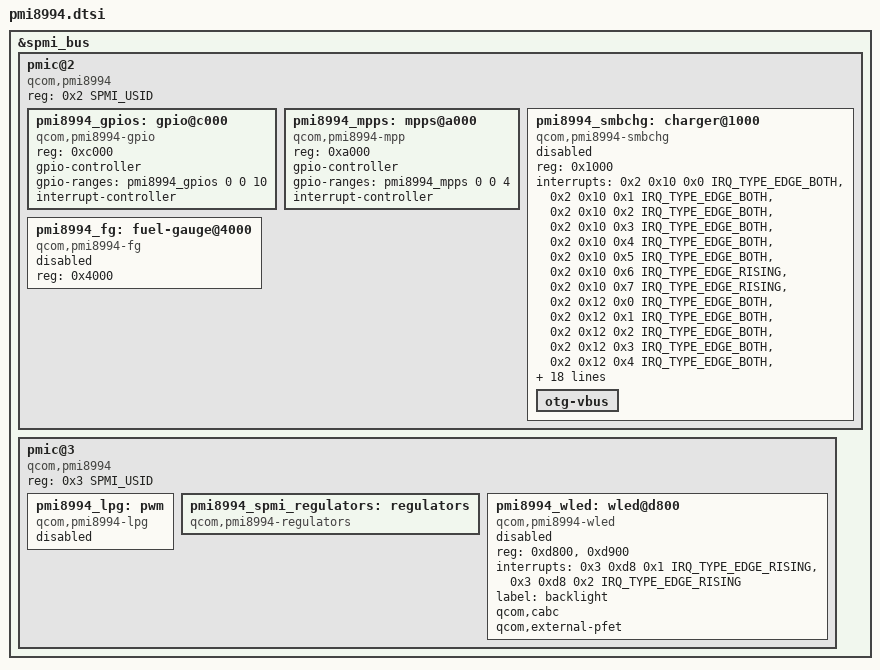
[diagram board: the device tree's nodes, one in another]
// SPDX-License-Identifier: GPL-2.0
#include <dt-bindings/interrupt-controller/irq.h>
#include <dt-bindings/spmi/spmi.h>

&spmi_bus {

	pmic@2 {
		compatible = "qcom,pmi8994", "qcom,spmi-pmic";
		reg = <0x2 SPMI_USID>;
		#address-cells = <1>;
		#size-cells = <0>;

		pmi8994_gpios: gpio@c000 {
			compatible = "qcom,pmi8994-gpio", "qcom,spmi-gpio";
			reg = <0xc000>;
			gpio-controller;
			gpio-ranges = <&pmi8994_gpios 0 0 10>;
			#gpio-cells = <2>;
			interrupt-controller;
			#interrupt-cells = <2>;
		};

		pmi8994_mpps: mpps@a000 {
			compatible = "qcom,pmi8994-mpp", "qcom,spmi-mpp";
			reg = <0xa000>;
			gpio-controller;
			gpio-ranges = <&pmi8994_mpps 0 0 4>;
			#gpio-cells = <2>;
			interrupt-controller;
			#interrupt-cells = <2>;
		};

		pmi8994_smbchg: charger@1000 {
			compatible = "qcom,pmi8994-smbchg";
			reg = <0x1000>;

			interrupts = <0x2 0x10 0x0 IRQ_TYPE_EDGE_BOTH>,
				     <0x2 0x10 0x1 IRQ_TYPE_EDGE_BOTH>,
				     <0x2 0x10 0x2 IRQ_TYPE_EDGE_BOTH>,
				     <0x2 0x10 0x3 IRQ_TYPE_EDGE_BOTH>,
				     <0x2 0x10 0x4 IRQ_TYPE_EDGE_BOTH>,
				     <0x2 0x10 0x5 IRQ_TYPE_EDGE_BOTH>,
				     <0x2 0x10 0x6 IRQ_TYPE_EDGE_RISING>,
				     <0x2 0x10 0x7 IRQ_TYPE_EDGE_RISING>,
				     <0x2 0x12 0x0 IRQ_TYPE_EDGE_BOTH>,
				     <0x2 0x12 0x1 IRQ_TYPE_EDGE_BOTH>,
				     <0x2 0x12 0x2 IRQ_TYPE_EDGE_BOTH>,
				     <0x2 0x12 0x3 IRQ_TYPE_EDGE_BOTH>,
				     <0x2 0x12 0x4 IRQ_TYPE_EDGE_BOTH>,
				     <0x2 0x12 0x5 IRQ_TYPE_EDGE_BOTH>,
				     <0x2 0x12 0x6 IRQ_TYPE_EDGE_BOTH>,
				     <0x2 0x12 0x7 IRQ_TYPE_EDGE_BOTH>,
				     <0x2 0x13 0x0 IRQ_TYPE_EDGE_BOTH>,
				     <0x2 0x13 0x1 IRQ_TYPE_EDGE_BOTH>,
				     <0x2 0x13 0x2 IRQ_TYPE_EDGE_BOTH>,
				     <0x2 0x13 0x3 IRQ_TYPE_EDGE_BOTH>,
				     <0x2 0x13 0x4 IRQ_TYPE_EDGE_RISING>,
				     <0x2 0x13 0x5 IRQ_TYPE_EDGE_RISING>,
				     <0x2 0x13 0x6 IRQ_TYPE_EDGE_FALLING>,
				     <0x2 0x14 0x0 IRQ_TYPE_EDGE_BOTH>,
				     <0x2 0x14 0x1 IRQ_TYPE_EDGE_BOTH>,
				     <0x2 0x16 0x0 IRQ_TYPE_EDGE_BOTH>,
				     <0x2 0x16 0x1 IRQ_TYPE_EDGE_BOTH>,
				     <0x2 0x16 0x2 IRQ_TYPE_EDGE_BOTH>,
				     <0x2 0x16 0x3 IRQ_TYPE_EDGE_BOTH>,
				     <0x2 0x16 0x4 IRQ_TYPE_EDGE_BOTH>,
				     <0x2 0x16 0x5 IRQ_TYPE_EDGE_BOTH>;
			interrupt-names = "chg-error",
					  "chg-inhibit",
					  "chg-prechg-sft",
					  "chg-complete-chg-sft",
					  "chg-p2f-thr",
					  "chg-rechg-thr",
					  "chg-taper-thr",
					  "chg-tcc-thr",
					  "batt-hot",
					  "batt-warm",
					  "batt-cold",
					  "batt-cool",
					  "batt-ov",
					  "batt-low",
					  "batt-missing",
					  "batt-term-missing",
					  "usbin-uv",
					  "usbin-ov",
					  "usbin-src-det",
					  "otg-fail",
					  "otg-oc",
					  "aicl-done",
					  "usbid-change",
					  "dcin-uv",
					  "dcin-ov",
					  "power-ok",
					  "temp-shutdown",
					  "wdog-timeout",
					  "flash-fail",
					  "otst2",
					  "otst3";

			status = "disabled";

			otg-vbus {};
		};

		pmi8994_fg: fuel-gauge@4000 {
			compatible = "qcom,pmi8994-fg";
			reg = <0x4000>;

			status = "disabled";
		};
	};

	pmic@3 {
		compatible = "qcom,pmi8994", "qcom,spmi-pmic";
		reg = <0x3 SPMI_USID>;
		#address-cells = <1>;
		#size-cells = <0>;

		pmi8994_lpg: pwm {
			compatible = "qcom,pmi8994-lpg";

			#address-cells = <1>;
			#size-cells = <0>;
			#pwm-cells = <2>;

			status = "disabled";
		};

		pmi8994_spmi_regulators: regulators {
			compatible = "qcom,pmi8994-regulators";
		};

		pmi8994_wled: wled@d800 {
			compatible = "qcom,pmi8994-wled";
			reg = <0xd800>, <0xd900>;
			interrupts = <0x3 0xd8 0x1 IRQ_TYPE_EDGE_RISING>,
				     <0x3 0xd8 0x2 IRQ_TYPE_EDGE_RISING>;
			interrupt-names = "ovp", "short";
			label = "backlight";

			qcom,cabc;
			qcom,external-pfet;

			status = "disabled";
		};
	};
};
